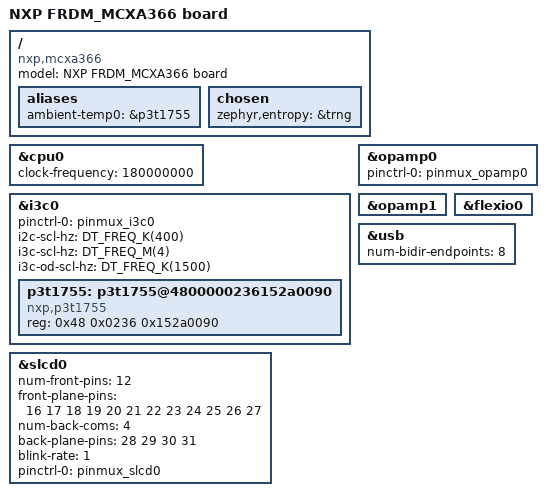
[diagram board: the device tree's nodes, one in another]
/*
 * Copyright 2025,2026 NXP
 *
 * SPDX-License-Identifier: Apache-2.0
 */

/dts-v1/;

#include <nxp/nxp_mcxa366.dtsi>
#include "frdm_mcxa366-pinctrl.dtsi"
#include "board_common.dtsi"
#include <freq.h>

/ {
	model = "NXP FRDM_MCXA366 board";
	compatible = "nxp,mcxa366", "nxp,mcx";

	aliases {
		ambient-temp0 = &p3t1755;
	};

	chosen {
		zephyr,entropy = &trng;
	};
};

&cpu0 {
	clock-frequency = <180000000>;
};

&i3c0 {
	status = "okay";
	pinctrl-0 = <&pinmux_i3c0>;
	pinctrl-names = "default";

	i2c-scl-hz = <DT_FREQ_K(400)>;
	i3c-scl-hz = <DT_FREQ_M(4)>;
	i3c-od-scl-hz = <DT_FREQ_K(1500)>;

	p3t1755: p3t1755@4800000236152a0090 {
		compatible = "nxp,p3t1755";
		reg = <0x48 0x0236 0x152a0090>;
		status = "okay";
	};
};

/* OPAMP configuration */
&opamp0 {
	pinctrl-0 = <&pinmux_opamp0>;
	pinctrl-names = "default";
	status = "okay";
};

&opamp1 {
	status = "okay";
};

&flexio0 {
	status = "okay";
};

zephyr_udc0: &usb {
	status = "okay";
	num-bidir-endpoints = <8>;
};

/* SLCD configuration */
&slcd0 {
	status = "okay";
	num-front-pins = <12>;
	front-plane-pins = <16 17 18 19 20 21 22 23 24 25 26 27>;
	num-back-coms = <4>;
	back-plane-pins = <28 29 30 31>;
	blink-rate = <1>;
	pinctrl-0 = <&pinmux_slcd0>;
	pinctrl-names = "default";
};

slcd_controller: &slcd0 {};
